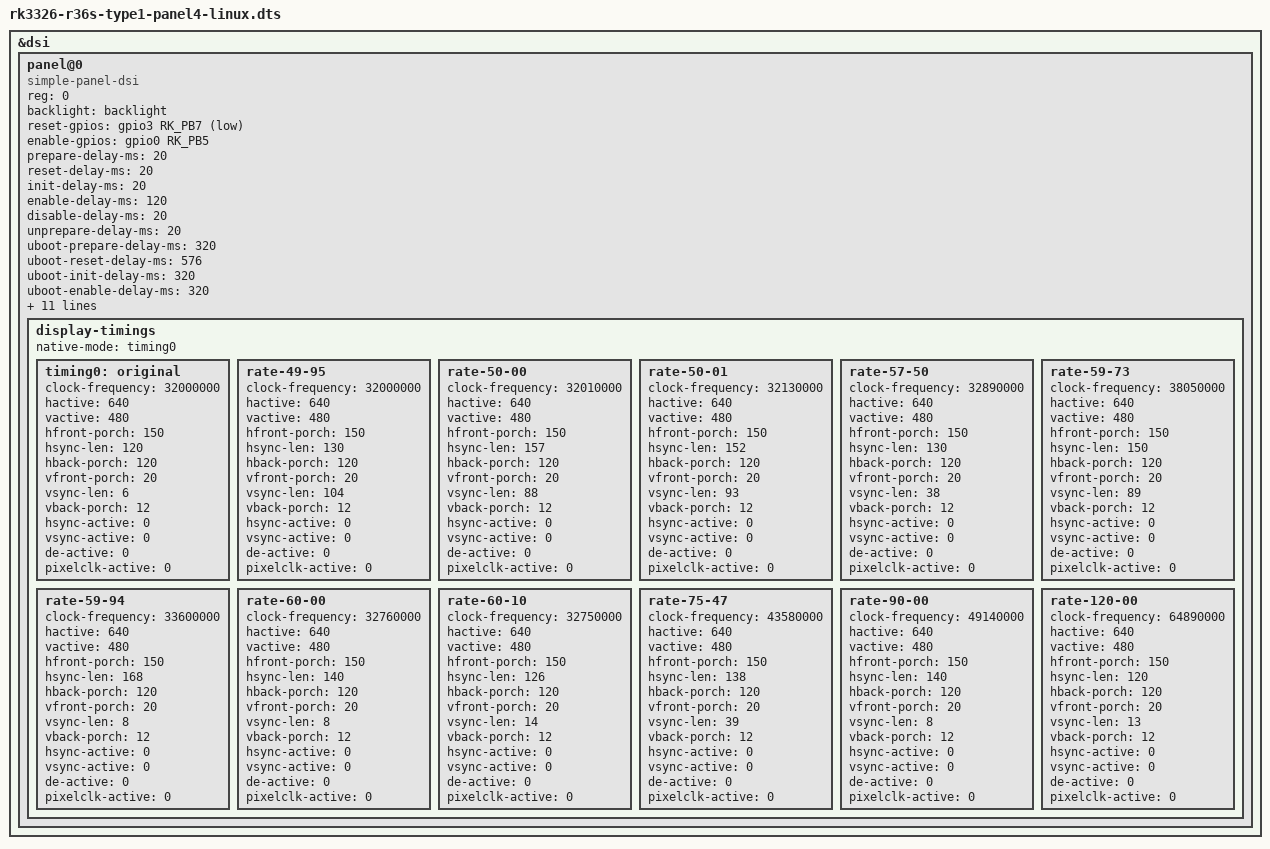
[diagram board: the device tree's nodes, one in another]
// SPDX-License-Identifier: (GPL-2.0+ OR MIT)
/*
* Copyright (c) 2025 kk&lcdyk
*
* R36S Clone掌机 种类1
*
*/

/dts-v1/;
#include "rk3326-r36s-type1-panel1-linux.dts"

&dsi {
	status = "okay";

	panel@0 {
		compatible = "simple-panel-dsi";
		reg = <0>;
		/* pwm1 backlight */
		backlight = <&backlight>;
		/* LCD reset gpio GPIO3.B7 */
		reset-gpios = <&gpio3 RK_PB7 GPIO_ACTIVE_LOW>;
		/* power-supply-gpio GPIO0.B5  */
		enable-gpios = <&gpio0 RK_PB5 GPIO_ACTIVE_HIGH>;
		prepare-delay-ms = <20>;
		reset-delay-ms = <20>;
		init-delay-ms = <20>;
		enable-delay-ms = <120>;
		disable-delay-ms = <20>;
		unprepare-delay-ms = <20>;
		uboot-prepare-delay-ms = <320>;
		uboot-reset-delay-ms = <576>;
		uboot-init-delay-ms = <320>;
		uboot-enable-delay-ms = <320>;
		uboot-disable-delay-ms = <320>;
		uboot-unprepare-delay-ms = <20>;
		width-mm = <153>;
		height-mm = <85>;
		dsi,flags  = <(MIPI_DSI_MODE_VIDEO |
		MIPI_DSI_MODE_VIDEO_BURST |
		MIPI_DSI_MODE_LPM |
		MIPI_DSI_MODE_EOT_PACKET)>;
		dsi,format = <MIPI_DSI_FMT_RGB888>;
		dsi,lanes = <4>;
		panel-init-sequence = [39 00 04 b9 f1 12 87 39 00 04 b2 78 04 70 39 00 0b b3 10 10 fc fc 03 ff 00 00 00 00 15 00 02 b4 80 15 00 03 b5 06 06 15 00 03 b6 a9 a9 39 00 05 b8 26 22 f0 13 39 00 1c ba 33 81 05 f9 0e 0e 20 00 00 00 00 00 00 00 44 25 00 91 0a 00 00 01 4f 01 00 00 37 39 00 02 bc 47 39 00 06 bf 02 10 00 80 04 39 00 0a c0 73 73 50 50 00 00 12 73 00 39 00 12 c1 25 c0 32 32 99 e4 77 77 cc cc ff ff 11 11 00 00 32 39 00 0d c7 10 00 0a 00 00 00 00 00 ed c5 00 a5 39 00 05 c8 10 40 1e 03 39 00 02 cc 0b 39 00 23 e0 00 0a 0f 29 3c 3f 41 38 08 0c 0f 12 14 12 13 12 19 00 0a 0f 29 3c 3f 41 38 08 0c 0f 12 14 12 13 12 19 39 00 08 e1 11 11 91 00 00 00 00 39 00 0f e3 07 07 0b 0b 0b 0b 00 00 00 00 ff 04 c0 10 39 00 40 e9 c8 10 0a 00 00 f0 81 12 31 23 4f 86 f0 81 47 08 00 00 10 00 00 00 00 00 10 00 00 00 88 88 08 f8 f4 46 60 02 28 88 88 88 88 18 f8 f5 57 71 13 38 88 88 00 00 00 01 00 00 00 00 00 00 00 00 00 39 00 3e ea 00 1a 00 00 00 00 00 00 00 00 00 00 88 f8 18 f8 83 31 17 75 58 88 88 88 f8 08 f8 82 20 06 64 48 88 88 23 00 00 02 fe 00 00 00 00 00 00 00 00 00 00 00 00 00 00 00 00 00 00 00 00 00 00 39 00 04 ef ff ff 01 05 fa 01 11 05 32 01 29];
		panel-exit-sequence = <0x5000128 0x5000110>;

		/delete-node/ display-timings;
		display-timings {
			native-mode = <&timing0>;

			// 32.00MHz / (640+150+120+120)×(480+20+6+12) = 1030×518 = 59.98 Hz
			timing0: original {
				clock-frequency = <32000000>;
				hactive = <640>;
				vactive = <480>;
				hfront-porch = <150>;
				hsync-len = <120>;
				hback-porch = <120>;
				vfront-porch = <20>;
				vsync-len = <6>;
				vback-porch = <12>;
				hsync-active = <0>;
				vsync-active = <0>;
				de-active = <0>;
				pixelclk-active = <0>;
			};
			/delete-node/ timing1;

			// 32.00MHz / (640+150+130+120)×(480+20+104+12) = 1040×616 = 49.95 Hz
			rate-49-95 {
				clock-frequency = <32000000>;
				hactive = <640>;
				vactive = <480>;
				hfront-porch = <150>;
				hsync-len = <130>;
				hback-porch = <120>;
				vfront-porch = <20>;
				vsync-len = <104>;
				vback-porch = <12>;
				hsync-active = <0>;
				vsync-active = <0>;
				de-active = <0>;
				pixelclk-active = <0>;
			};

			// 32.01MHz / (640+150+157+120)×(480+20+88+12) = 1067×600 = 50.00 Hz
			rate-50-00 {
				clock-frequency = <32010000>;
				hactive = <640>;
				vactive = <480>;
				hfront-porch = <150>;
				hsync-len = <157>;
				hback-porch = <120>;
				vfront-porch = <20>;
				vsync-len = <88>;
				vback-porch = <12>;
				hsync-active = <0>;
				vsync-active = <0>;
				de-active = <0>;
				pixelclk-active = <0>;
			};

			// 32.13MHz / (640+150+152+120)×(480+20+93+12) = 1062×605 = 50.01 Hz
			rate-50-01 {
				clock-frequency = <32130000>;
				hactive = <640>;
				vactive = <480>;
				hfront-porch = <150>;
				hsync-len = <152>;
				hback-porch = <120>;
				vfront-porch = <20>;
				vsync-len = <93>;
				vback-porch = <12>;
				hsync-active = <0>;
				vsync-active = <0>;
				de-active = <0>;
				pixelclk-active = <0>;
			};

			// 32.89MHz / (640+150+130+120)×(480+20+38+12) = 1040×550 = 57.50 Hz
			rate-57-50 {
				clock-frequency = <32890000>;
				hactive = <640>;
				vactive = <480>;
				hfront-porch = <150>;
				hsync-len = <130>;
				hback-porch = <120>;
				vfront-porch = <20>;
				vsync-len = <38>;
				vback-porch = <12>;
				hsync-active = <0>;
				vsync-active = <0>;
				de-active = <0>;
				pixelclk-active = <0>;
			};

			// 38.05MHz / (640+150+150+120)×(480+20+89+12) = 1060×601 = 59.73 Hz
			rate-59-73 {
				clock-frequency = <38050000>;
				hactive = <640>;
				vactive = <480>;
				hfront-porch = <150>;
				hsync-len = <150>;
				hback-porch = <120>;
				vfront-porch = <20>;
				vsync-len = <89>;
				vback-porch = <12>;
				hsync-active = <0>;
				vsync-active = <0>;
				de-active = <0>;
				pixelclk-active = <0>;
			};

			// 33.60MHz / (640+150+168+120)×(480+20+8+12) = 1078×520 = 59.94 Hz
			rate-59-94 {
				clock-frequency = <33600000>;
				hactive = <640>;
				vactive = <480>;
				hfront-porch = <150>;
				hsync-len = <168>;
				hback-porch = <120>;
				vfront-porch = <20>;
				vsync-len = <8>;
				vback-porch = <12>;
				hsync-active = <0>;
				vsync-active = <0>;
				de-active = <0>;
				pixelclk-active = <0>;
			};

			// 32.76MHz / (640+150+140+120)×(480+20+8+12) = 1050×520 = 60.00 Hz
			rate-60-00 {
				clock-frequency = <32760000>;
				hactive = <640>;
				vactive = <480>;
				hfront-porch = <150>;
				hsync-len = <140>;
				hback-porch = <120>;
				vfront-porch = <20>;
				vsync-len = <8>;
				vback-porch = <12>;
				hsync-active = <0>;
				vsync-active = <0>;
				de-active = <0>;
				pixelclk-active = <0>;
			};

			// 32.75MHz / (640+150+126+120)×(480+20+14+12) = 1036×526 = 60.10 Hz
			rate-60-10 {
				clock-frequency = <32750000>;
				hactive = <640>;
				vactive = <480>;
				hfront-porch = <150>;
				hsync-len = <126>;
				hback-porch = <120>;
				vfront-porch = <20>;
				vsync-len = <14>;
				vback-porch = <12>;
				hsync-active = <0>;
				vsync-active = <0>;
				de-active = <0>;
				pixelclk-active = <0>;
			};

			// 43.58MHz / (640+150+138+120)×(480+20+39+12) = 1048×551 = 75.47 Hz
			rate-75-47 {
				clock-frequency = <43580000>;
				hactive = <640>;
				vactive = <480>;
				hfront-porch = <150>;
				hsync-len = <138>;
				hback-porch = <120>;
				vfront-porch = <20>;
				vsync-len = <39>;
				vback-porch = <12>;
				hsync-active = <0>;
				vsync-active = <0>;
				de-active = <0>;
				pixelclk-active = <0>;
			};

			// 49.14MHz / (640+150+140+120)×(480+20+8+12) = 1050×520 = 90.00 Hz
			rate-90-00 {
				clock-frequency = <49140000>;
				hactive = <640>;
				vactive = <480>;
				hfront-porch = <150>;
				hsync-len = <140>;
				hback-porch = <120>;
				vfront-porch = <20>;
				vsync-len = <8>;
				vback-porch = <12>;
				hsync-active = <0>;
				vsync-active = <0>;
				de-active = <0>;
				pixelclk-active = <0>;
			};

			// 64.89MHz / (640+150+120+120)×(480+20+13+12) = 1030×525 = 120.00 Hz
			rate-120-00 {
				clock-frequency = <64890000>;
				hactive = <640>;
				vactive = <480>;
				hfront-porch = <150>;
				hsync-len = <120>;
				hback-porch = <120>;
				vfront-porch = <20>;
				vsync-len = <13>;
				vback-porch = <12>;
				hsync-active = <0>;
				vsync-active = <0>;
				de-active = <0>;
				pixelclk-active = <0>;
			};
		};
	};
};
